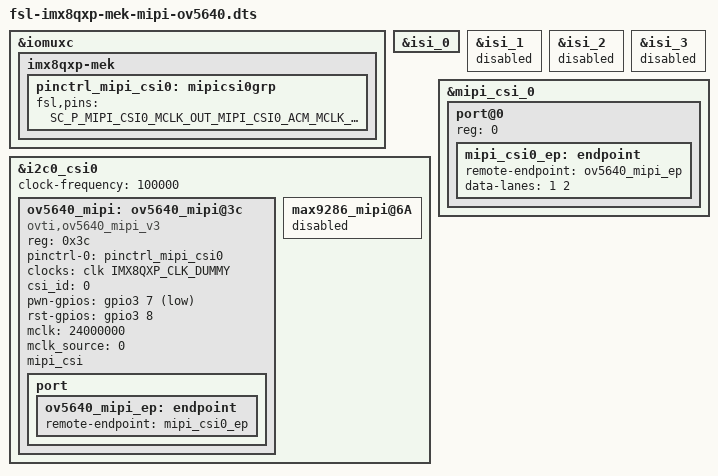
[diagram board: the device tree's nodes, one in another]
/*
 * Copyright 2018 NXP
 *
 * This program is free software; you can redistribute it and/or
 * modify it under the terms of the GNU General Public License
 * as published by the Free Software Foundation; either version 2
 * of the License, or (at your option) any later version.
 *
 * This program is distributed in the hope that it will be useful,
 * but WITHOUT ANY WARRANTY; without even the implied warranty of
 * MERCHANTABILITY or FITNESS FOR A PARTICULAR PURPOSE.  See the
 * GNU General Public License for more details.
 */

#include "fsl-imx8qxp-mek.dts"
#include "fsl-imx8qxp-mek-lvds0-it6263.dtsi"

&iomuxc {
	imx8qxp-mek {
		pinctrl_mipi_csi0: mipicsi0grp{
			fsl,pins = <
				SC_P_MIPI_CSI0_MCLK_OUT_MIPI_CSI0_ACM_MCLK_OUT	0xC0000041
				SC_P_MIPI_CSI0_GPIO0_01_LSIO_GPIO3_IO07		0xC0000041
				SC_P_MIPI_CSI0_GPIO0_00_LSIO_GPIO3_IO08		0xC0000041
			>;
		};
	};
};

&isi_0 {
	status = "okay";
};

&isi_1 {
	status = "disabled";
};

&isi_2 {
	status = "disabled";
};

&isi_3 {
	status = "disabled";
};

&i2c0_csi0 {
	clock-frequency = <100000>;
	status = "okay";

	ov5640_mipi: ov5640_mipi@3c {
		compatible = "ovti,ov5640_mipi_v3";
		reg = <0x3c>;
		pinctrl-names = "default";
		pinctrl-0 = <&pinctrl_mipi_csi0>;
		clocks = <&clk IMX8QXP_CLK_DUMMY>;
		clock-names = "csi_mclk";
		csi_id = <0>;
		pwn-gpios = <&gpio3 7 GPIO_ACTIVE_LOW>;
		rst-gpios = <&gpio3 8 GPIO_ACTIVE_HIGH>;
		mclk = <24000000>;
		mclk_source = <0>;
		mipi_csi;
		status = "okay";
		port {
			ov5640_mipi_ep: endpoint {
				remote-endpoint = <&mipi_csi0_ep>;
			};
		};
	};

	max9286_mipi@6A {
		status = "disabled";
	};
};

&mipi_csi_0 {
	/delete-property/virtual-channel;
	status = "okay";

	port@0 {
		reg = <0>;
		mipi_csi0_ep: endpoint {
			remote-endpoint = <&ov5640_mipi_ep>;
			data-lanes = <1 2>;
		};
	};
};
